# NUC1311AE_v1 register map
File version: 1.0
Registers are 32-bit, read-write, reset 0x0 unless marked. A register's access mark holds for its fields unless they carry their own. Offsets are from the block's base; [hi:lo] are bit positions; 'fields as' and 'values as' point back to an identical list.

## TMR23 — TIMER Register Map
Base 0x40110000
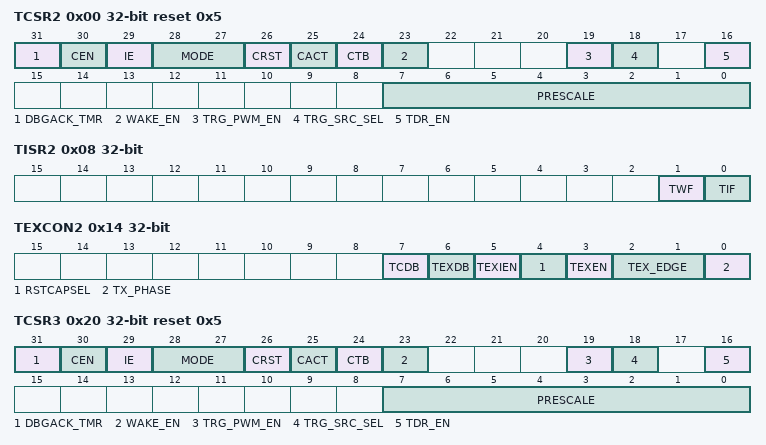
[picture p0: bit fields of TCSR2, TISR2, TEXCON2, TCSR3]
0x00 TCSR2 reset 0x5 — Timer2 Control and Status Register
  [31] DBGACK_TMR — ICE Debug Mode Acknowledge Disable Control (Write Protect). TIMER counter will keep going no matter CPU is held by ICE or not.
    0=ICE debug mode acknowledgement effects TIMER counting; 1=ICE debug mode acknowledgement Disabled
  [30] CEN — Timer Enable Control
    0=Stops/Suspends counting; 1=Starts counting
  [29] IE — Interrupt Enable Control. If this bit is enabled, when the timer interrupt flag TIF (TISR[0]) is set to 1, the timer interrupt signal is generated and inform to CPU.
    0=Timer Interrupt function Disabled; 1=Timer Interrupt function Enabled
  [28:27] MODE — Timer Operating Mode
    0=The Timer controller is operated in One-shot mode; 1=The Timer controller is operated in Periodic mode; 2=The Timer controller is operated in Toggle-output mode; 3=The Timer controller is operated in Continuous Counting mode
  [26] CRST — Timer Reset
    0=No effect; 1=Reset 8-bit prescale counter, 24-bit up counter value and CEN bit if CACT is 1
  [25] CACT ro — Timer Active Status (Read Only). This bit indicates the 24-bit up counter status.
    0=24-bit up counter is not active; 1=24-bit up counter is active
  [24] CTB — Counter Mode Enable Control. This bit is for external counting pin function enabled. When timer is used as an event counter, this bit should be set to 1 and select HCLK as timer clock source. Please refer to 6.6.5.6 for detail description.
    0=External counter mode Disabled; 1=External counter mode Enabled
  [23] WAKE_EN — Wake Up Function Enable Control
    0=Wake-up trigger event Disabled; 1=Wake-up trigger event Enabled
  [19] TRG_PWM_EN — Trigger PWM Enable Control. If this bit is set to 1, timer time-out interrupt or capture interrupt can be triggered PWM.
    0=Timer interrupt trigger PWM Disabled; 1=If TRG_SRC_SEL (TCSR[18]) = 0, time-out interrupt signal will trigger PWM
  [18] TRG_SRC_SEL — Trigger Source Select Bit. This bit is used to select trigger source is from Timer time-out interrupt signal or capture interrupt signal.
    0=Timer time-out interrupt signal is used to trigger PWM; 1=Capture interrupt signal is used to trigger PWM
  [16] TDR_EN — Data Load Enable Control. When TDR_EN is set, TDR (Timer Data Register) will be updated continuously with the 24-bit up-timer value as the timer is counting.
    0=Timer Data Register update Disabled; 1=Timer Data Register update Enabled while Timer counter is active
  [7:0] PRESCALE — Prescale Counter
0x04 TCMPR2 — Timer2 Compare Register
  [23:0] TCMP — Timer Compared Value. TCMP is a 24-bit compared value register. When the internal 24-bit up counter value is equal to TCMP value, the TIF flag will set to 1. Note1: Never write 0x0 or 0x1 in TCMP field, or the core will run into unknown state. Note2: When timer is operating at continuous counting mode, the 24-bit up counter will keep counting continuously even if user writes a new value into TCMP field. But if timer is operating at other modes, the 24-bit up counter will restart counting and using newest TCMP value to be the timer compared value if user writes a new value into TCMP field.
0x08 TISR2 — Timer2 Interrupt Status Register
  [1] TWF — Timer Wake-Up Flag. This bit indicates the interrupt wake-up flag status of Timer. Note: This bit is cleared by writing 1 to it.
    0=Timer does not cause CPU wake-up; 1=CPU wake-up from Idle or Power-down mode if Timer time-out interrupt signal generated
  [0] TIF — Timer Interrupt Flag. This bit indicates the interrupt flag status of Timer while TDR value reaches to TCMP value. Note: This bit is cleared by writing 1 to it.
    0=No effect; 1=TDR value matches the TCMP value
0x0C TDR2 ro — Timer2 Data Register
  [23:0] TDR — Timer Data Register. If TDR_EN (TCSR[16]) is set to 1, TDR register will be updated continuously to monitor 24-bit up counter value.
0x10 TCAP2 ro — Timer2 Capture Data Register
  [23:0] TCAP — Timer Capture Data Register. When TEXIF (TEXISR[0]) flag and RSTCAPSEL (TEXCON[4]) is set to 1, the current TDR value will be auto-loaded into this TCAP filed immediately.
0x14 TEXCON2 — Timer2 External Control Register
  [7] TCDB — Timer External Counter Input Pin De-Bounce Enable Control. If this bit is enabled, the edge detection of TMx pin is detected with de-bounce circuit.
    0=TMx pin de-bounce Disabled; 1=TMx pin de-bounce Enabled
  [6] TEXDB — Timer External Capture Input Pin De-Bounce Enable Control. If this bit is enabled, the edge detection of TMx_EXT pin is detected with de-bounce circuit.
    0=TMx_EXT pin de-bounce Disabled; 1=TMx_EXT pin de-bounce Enabled
  [5] TEXIEN — Timer External Capture Interrupt Enable Control. If TEXIEN enabled, Timer will raise an external capture interrupt signal and inform to CPU while TEXIF flag is set to 1.
    0=TMx_EXT pin detection Interrupt Disabled; 1=TMx_EXT pin detection Interrupt Enabled
  [4] RSTCAPSEL — Timer External Reset Counter / Timer External Capture Mode Selection
    0=Transition on TMx_EXT pin is using to save the TDR value into TCAP.(event capture function); 1=Transition on TMx_EXT pin is using to reset the 24-bit up counter.(event reset counter function)
  [3] TEXEN — Timer External Pin Function Enable Control. This bit enables the RSTCAPSEL function on the TMx_EXT pin.
    0=RSTCAPSEL function of TMx_EXT pin will be ignored; 1=RSTCAPSEL function of TMx_EXT pin is active
  [2:1] TEX_EDGE — Timer External Capture Pin Edge Detect Selection
    0=A 1 to 0 transition on TMx_EXT pin will be detected; 1=A 0 to 1 transition on TMx_EXT pin will be detected; 2=Either 1 to 0 or 0 to 1 transition on TMx_EXT pin will be detected
  [0] TX_PHASE — Timer External Count Pin Phase Detect Selection. This bit indicates the detection phase of TMx_EXT pin.
    0=A falling edge of TMx_EXT pin will be counted; 1=A rising edge of TMx_EXT pin will be counted
0x18 TEXISR2 — Timer2 External Interrupt Status Register
  [0] TEXIF — Timer External Capture Interrupt Flag. This bit indicates the external capture interrupt flag status. When TEXEN (TEXCON[3]) enabled, TMx_EXT pin selected as external capture function, and a transition on TMx_EXT pin matched the TEX_EDGE (TEXCON[2:1]) setting, this flag will set to 1 by hardware. Note: This bit is cleared by writing 1 to it.
    0=TMx_EXT pin interrupt did not occur; 1=TMx_EXT pin interrupt occurred
0x20 TCSR3 reset 0x5 — Timer3 Control and Status Register
  fields as TCSR2
0x24 TCMPR3 — Timer3 Compare Register
  fields as TCMPR2
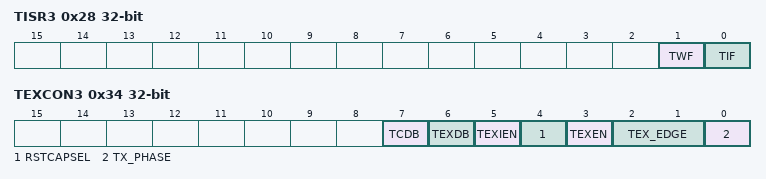
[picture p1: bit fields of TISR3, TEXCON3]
0x28 TISR3 — Timer3 Interrupt Status Register
  fields as TISR2
0x2C TDR3 ro — Timer3 Data Register
  fields as TDR2
0x30 TCAP3 ro — Timer3 Capture Data Register
  fields as TCAP2
0x34 TEXCON3 — Timer3 External Control Register
  fields as TEXCON2
0x38 TEXISR3 — Timer3 External Interrupt Status Register
  fields as TEXISR2
